# DA1469x register map
Vendor: Dialog; Series: DA1469x; File version: 1.2
CPU: CM33 r1p0, little endian, no MPU, FPU, 3 interrupt priority bits
Registers are 32-bit, read-write, reset 0x0 unless marked. A register's access mark holds for its fields unless they carry their own. Offsets are from the block's base; [hi:lo] are bit positions.

## CHARGER (part 2 of 2) — CHARGER registers
Base 0x50040400
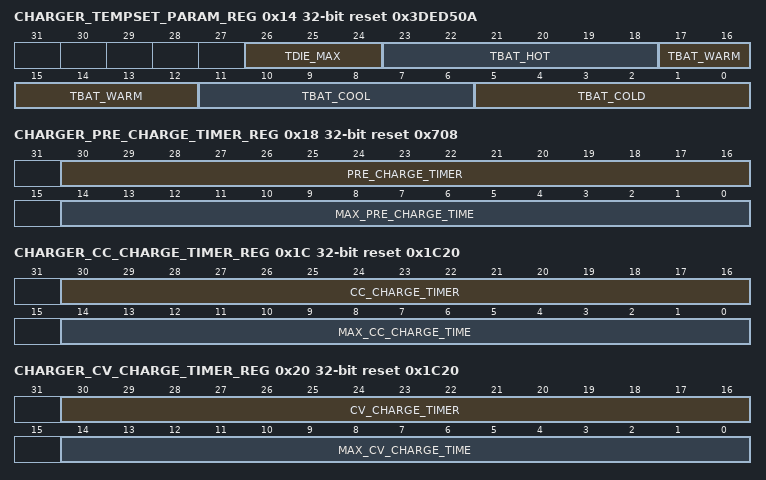
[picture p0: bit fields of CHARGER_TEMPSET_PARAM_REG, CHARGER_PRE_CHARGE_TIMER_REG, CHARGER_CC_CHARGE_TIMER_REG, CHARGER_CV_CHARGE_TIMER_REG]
0x14 CHARGER_TEMPSET_PARAM_REG reset 0x3DED50A — Charger battery temperature settings register
  [26:24] TDIE_MAX — This bit-field determines the maximum Die temperature level limit, ranging from 0C to 130C, according to the following encoding: 000: 0 C (mainly for test purposes) 001: 50 C 010: 80 C 011: 90 C 100: 100 C 101: 110 C 110: 120 C 111: 130 C
  [23:18] TBAT_HOT — This bit-field determines the battery temperature above which the charge current is zero, defining the "Hot" battery temperature zone. It ranges from minus 10C to 53C. The range is the same with the one defined in detail in TBAT_COLD bit-field.
  [17:12] TBAT_WARM — This bit-field determines the battery temperature above which the charge current is reduced, defining the "Warm" temperature zone. It ranges from minus 10C to 53C. The range is the same with the one defined in detail in TBAT_COLD bit-field.
  [11:6] TBAT_COOL — This bit-field determines the battery temperature below which the charge current is reduced, defining the "Cool" temperature zone. It ranges from minus 10C to 53C and the range is the same with the one defined in TBAT_COLD bit-field.
  [5:0] TBAT_COLD — This bit-field determines the battery temperature below which the charge current is zero, defining the "Cold" temperature zone. It ranges from minus 10C to 53C, according to the following encoding: 0 : -10 C 1 : -9 C 2 : -8 C 3 : -7 C 4 : -6 C 5 : -5 C 6 : -4 C 7 : -3 C 8 : -2 C 9 : -1 C 10 : 0 C 11 : 1 C 12 : 2 C 13 : 3 C 14 : 4 C 15 : 5 C 16 : 6 C 17 : 7 C 18 : 8 C 19 : 9 C 20 : 10 C 21 : 11 C 22 : 12 C 23 : 13 C 24 : 14 C 25 : 15 C 26 : 16 C 27 : 17 C 28 : 18 C 29 : 19 C 30 : 20 C 31 : 21 C 32 : 22 C 33 : 23 C 34 : 24 C 35 : 25 C 36 : 26 C 37 : 27 C 38 : 28 C 39 : 29 C 40 : 30 C 41 : 31 C 42 : 32 C 43 : 33 C 44 : 34 C 45 : 35 C 46 : 36 C 47 : 37 C 48 : 38 C 49 : 39 C 50 : 40 C 51 : 41 C 52 : 42 C 53 : 43 C 54 : 44 C 55 : 45 C 56 : 46 C 57 : 47 C 58 : 48 C 59 : 49 C 60 : 50 C 61 : 51 C 62 : 52 C 63 : 53 C
0x18 CHARGER_PRE_CHARGE_TIMER_REG reset 0x708 — Maximum pre-charge time limit register
  [30:16] PRE_CHARGE_TIMER ro — Returns the current value of the Pre-Charge timeout counter, running at a 1Hz clock. The range of the specific timer is identical to the one of the CC-Charge and the CV-Charge timers, so it may count up to 6 hours, ranging from 0 to MAX_PRE_CHARGE_TIME. It is reset to 0 when the Charger's FSM is either in DISABLED or in END_OF_CHARGE state.
  [14:0] MAX_PRE_CHARGE_TIME — This bit-field determines the maximum time (measured in ticks of the Charger's 1Hz clock) allowed for the Pre-Charge stage. If this is exceeded, a Pre-Charge time-out error will be captured by the Charger's control unit and its FSM will move to the respective state (ERROR). In order to exit this state and re-start charging, the CHARGER_RESUME bit-field of CHARGER_CTRL_REG must be set. Note: The specific bit-field should be always set to a non-zero value.
0x1C CHARGER_CC_CHARGE_TIMER_REG reset 0x1C20 — Maximum CC-charge time limit register
  [30:16] CC_CHARGE_TIMER ro — Returns the current value of the CC-Charge timeout counter, running at a 1Hz clock. The range of the specific timer is identical to the one of the Pre-Charge and the CV-Charge timers, so it may count up to 6 hours, ranging from 0 to MAX_CC_CHARGE_TIME. It is reset to 0 when the Charger's FSM is either in DISABLED or in END_OF_CHARGE state.
  [14:0] MAX_CC_CHARGE_TIME — This bit-field determines the maximum time (measured in ticks of the Charger's 1Hz clock) allowed for the CC (Constant Current) charging stage. If this is exceeded, a CC charge time-out error will be captured by the Charger's control unit and its FSM will move to the ERROR state. In order to exit this state and re-start charging, the CHARGER_RESUME bit-field of CHARGER_CTRL_REG must be set. Note: The specific bit-field should be always set to a non-zero value.
0x20 CHARGER_CV_CHARGE_TIMER_REG reset 0x1C20 — Maximum CV-charge time limit register
  [30:16] CV_CHARGE_TIMER ro — Returns the current value of the CV-Charge timeout counter, running at a 1Hz clock. The range of the specific timer is identical to the one of the Pre-Charge and the CC-Charge timers, so it may count up to 6 hours, ranging from 0 to MAX_CV_CHARGE_TIME. It is reset to 0 when the Charger's FSM is either in DISABLED or in END_OF_CHARGE state.
  [14:0] MAX_CV_CHARGE_TIME — This bit-field determines the maximum time (measured in ticks of the Charger's 1Hz clock) allowed for the CV (Constant Voltage) charging stage. If this is exceeded, a CV charge time-out error will be captured by the Charger's control unit and its FSM will move to the ERROR state. In order to exit this state and re-start charging, the CHARGER_RESUME bit-field of CHARGER_CTRL_REG must be set. Note: The specific bit-field should be always set to a non-zero value.
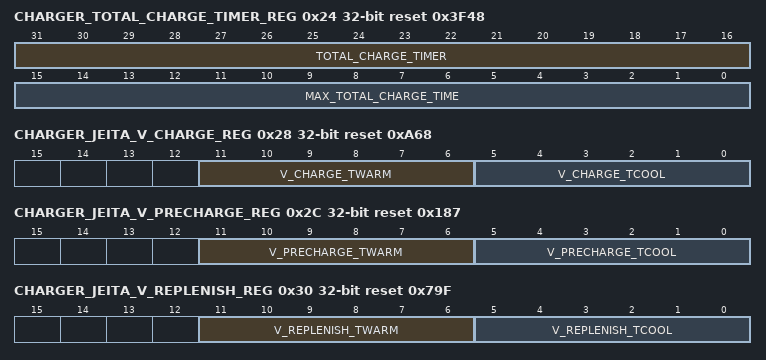
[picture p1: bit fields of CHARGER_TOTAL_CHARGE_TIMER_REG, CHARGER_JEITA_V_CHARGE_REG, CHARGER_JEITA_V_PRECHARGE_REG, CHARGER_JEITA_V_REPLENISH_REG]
0x24 CHARGER_TOTAL_CHARGE_TIMER_REG reset 0x3F48 (reset mask 0x7FFFFFFF) — Maximum total charge time limit register
  [31:16] TOTAL_CHARGE_TIMER ro — Returns the current value of the overall charge timeout counter, running at a 1Hz clock. This timer has been set to 16 bits, so that it can count up to 10.5 hours, and ranges from 0 to MAX_TOTAL_CHARGE_TIME. It is reset to 0 when the Charger's FSM is either in DISABLED or in END_OF_CHARGE state.
  [15:0] MAX_TOTAL_CHARGE_TIME — This bit-field determines the maximum overall charging time allowed (measured in ticks of the 1Hz clock). If this is exceeded, a total charge time-out error will be captured by the Charger's controller and its FSM will move to the ERROR state. An IRQ will be also generated if the respective IRQ mask bit of CHARGER_ERROR_IRQ_MASK_REG is already set. In order to to exit this state, the "CHARGER_RESUME" bit-field of CHARGER_CTRL_REG must be set, to enable the Charger's FSM switch from ERROR to DISABLED state and start-over. Note: The specific bit-field should be always set to a non-zero value.
0x28 CHARGER_JEITA_V_CHARGE_REG reset 0xA68 — JEITA-compliant Charge voltage settings register
  [11:6] V_CHARGE_TWARM — Charge voltage setting for the Warm battery temperature zone. Regarding the range of values of this bit-field, see also the description of V_CHARGE field of CHARGER_VOLTAGE_PARAM_REG register.
  [5:0] V_CHARGE_TCOOL — Charge voltage setting for the Cool battery temperature zone. Regarding the range of values of this bit-field, see also the description of V_CHARGE field of CHARGER_VOLTAGE_PARAM_REG register.
0x2C CHARGER_JEITA_V_PRECHARGE_REG reset 0x187 — JEITA-compliant Pre-Charge voltage settings register
  [11:6] V_PRECHARGE_TWARM — Pre-Charge voltage setting for the Warm battery temperature zone. Regarding the range of values of this bit-field, see also the description of V_CHARGE field of CHARGER_VOLTAGE_PARAM_REG register.
  [5:0] V_PRECHARGE_TCOOL — Pre-Charge current setting for the Cool battery temperature zone. Regarding the range of values of this bit-field, see also the description of V_CHARGE field of CHARGER_VOLTAGE_PARAM_REG register.
0x30 CHARGER_JEITA_V_REPLENISH_REG reset 0x79F — JEITA-compliant Replenish settings register
  [11:6] V_REPLENISH_TWARM — Replenish voltage setting for the Warm battery temperature zone. Regarding the range of values of this bit-field, see also the description of V_CHARGE field of CHARGER_VOLTAGE_PARAM_REG.
  [5:0] V_REPLENISH_TCOOL — Replenish voltage setting for the Cool battery temperature zone. Regarding the range of values of this bit-field, see also the description of V_CHARGE field of CHARGER_VOLTAGE_PARAM_REG.
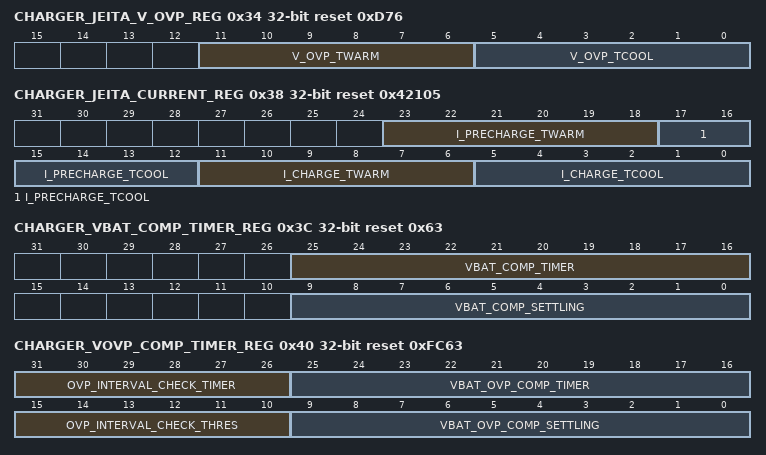
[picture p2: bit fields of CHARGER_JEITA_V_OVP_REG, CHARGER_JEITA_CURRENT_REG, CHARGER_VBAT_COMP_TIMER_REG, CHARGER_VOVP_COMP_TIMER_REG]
0x34 CHARGER_JEITA_V_OVP_REG reset 0xD76 — JEITA-compliant OVP settings register
  [11:6] V_OVP_TWARM — VBAT Over-voltage Protection (OVP) setting for the Warm battery temperature zone.Regarding the range of values of this bit-field, see also the description of V_CHARGE field of CHARGER_VOLTAGE_PARAM_REG.
  [5:0] V_OVP_TCOOL — VBAT Over-voltage Protection (OVP) setting for the Cool battery temperature zone.Regarding the range of values of this bit-field, see also the description of V_CHARGE field of CHARGER_VOLTAGE_PARAM_REG.
0x38 CHARGER_JEITA_CURRENT_REG reset 0x42105 — JEITA-compliant current settings register
  [23:18] I_PRECHARGE_TWARM — Pre-Charge current setting for the Warm battery temperature zone. Regarding the range of values of this bit-field, see also the description of I_PRECHARGE field of CHARGER_CURRENT_PARAM_REG register.
  [17:12] I_PRECHARGE_TCOOL — Pre-Charge current setting for the Cool battery temperature zone. Regarding the range of values of this bit-field, see also the description of I_PRECHARGE field of CHARGER_CURRENT_PARAM_REG register.
  [11:6] I_CHARGE_TWARM — Charge current setting for the Warm battery temperature pack zone. Regarding the range of values of this bit-field, see also the description of I_CHARGE field of CHARGER_CURRENT_PARAM_REG register.
  [5:0] I_CHARGE_TCOOL — Charge current setting for the "COOL" battery temperature level. Regarding the range of values of this bit-field, see also the description of I_CHARGE field of CHARGER_CURRENT_PARAM_REG register.
0x3C CHARGER_VBAT_COMP_TIMER_REG reset 0x63 — Main Vbat comparator timer register
  [25:16] VBAT_COMP_TIMER ro — Returns the current value of the timer used to determine when the output of the Vbat comparator (checking Vbat vs Pre_Charge and Replenish levels) must be sampled by the digital. As soon as the timer expires (down-counting to 0, starting from the value set in VBAT_COMP_SETTLING), the comparator's output is latched by the Charger's digital block and used by the FSM. Note: When the Charger's FSM is in BYPASSED state, this timer is kept to zero and the SW takes over. In this mode, the specific comparator checks the level of Vbat against the Pre-Charge level. Hence, SW can periodically sample the status of this comparator by reading the MAIN_VBAT_COMP_OUT bit-field of CHARGER_STATUS_REG, to determine if Vbat has exceeded the Pre-Charge level or not.
  [9:0] VBAT_COMP_SETTLING — Settling time threshold (in us) for the Vbat comparator checking Vbat vs the programmed Pre-Charge and Replenish levels. The settings (voltage levels) of the comparator are controlled by the digital block of the Charger and they are driven based on the state of the main FSM (PRE_CHARGE, END_OF_CHARGE).
0x40 CHARGER_VOVP_COMP_TIMER_REG reset 0xFC63 (reset mask 0x7FFFFFFF) — Vbat OVP comparator timer register
  [31:26] OVP_INTERVAL_CHECK_TIMER ro — The specific bit-field determines the current state of the timer used to periodically check the output of the Over-Voltage Protection comparator's output signal, as soon as the Charger's FSM reaches any of the charging states (PRE/CC/CV_CHARGE). When this happens, the timer starts ticking with the 1Mhz clock, ranging from 0 up to the programmed interval threshold (see also OVP_INTERVAL_CHECK_THRES field). As soon as this timer reaches the programmed threshold value, the Vbat OVP comparator's output is evaluated, increasing or not the counter keeping the consecutive OVP events. It is noted that out of the charging states, the specific timer is kept frozen to zero, not counting. Note : See also the OVP_OCCURRENCES_CNT bit-field of CHARGER_STATUS_REG for the consecutive OVP events counter.
  [25:16] VBAT_OVP_COMP_TIMER ro — Returns the current value of the timer used to determine when the Vbat Over-Voltage protection (OVP) comparator's output must be sampled by the digital. As soon as the timer expires (down-counting to 0, starting from VBAT_OVP_COMP_SETTLING), the comparator's output is latched by the Charger's digital block and used by the main FSM. Note: When the Charger's FSM is in BYPASSED state, this timer is kept to zero and the SW takes over, sampling the status of the VBAT_OVP_COMP_OUT bit-field of CHARGER_STATUS_REG to determine if the Vbat has exceeded the OVP limit.
  [15:10] OVP_INTERVAL_CHECK_THRES — This bit-field determines the periodic interval of checking the dedicated Vbat OVP comparator's output, when the Charger's FSM is in any of the charging states (PRE/CC/CV_CHARGE). The implementation is based on a dedicated timer, counting from zero up to the value programmed into this bit-field (see also OVP_INTERVAL_CHECK_TIMER field's description) and only when the FSM is in any of the three charging states. Out of these states, the timer is kept frozen to zero. As soon as this timer reaches the programmed threshold, the Vbat OVP comparator's output is sampled and depending on its level, (high or low), another counter, keeping the number of consecutive OVP events, is increased or not. The programmed threshold value should always be non-zero. Note: See also the OVP_DEBOUNCE_CNT bit-field of CHARGER_STATUS_REG, for the consecutive OVP events counter.
  [9:0] VBAT_OVP_COMP_SETTLING — Settling time threshold (in us) for the Vbat comparator checking Vbat vs the programmed Over-Voltage level.
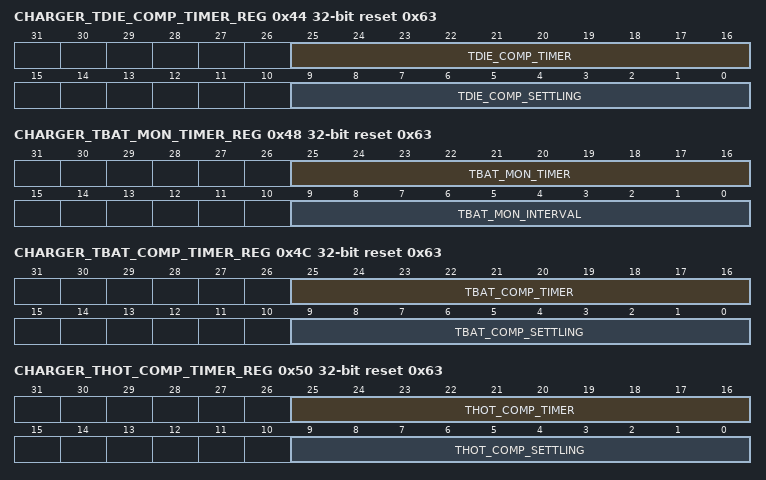
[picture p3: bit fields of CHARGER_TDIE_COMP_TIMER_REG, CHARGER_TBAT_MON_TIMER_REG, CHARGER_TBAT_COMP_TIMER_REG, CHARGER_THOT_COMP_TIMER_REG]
0x44 CHARGER_TDIE_COMP_TIMER_REG reset 0x63 — Die temperature comparator timer register
  [25:16] TDIE_COMP_TIMER ro — Returns the current value of the timer used to determine when the Die temperature comparator's output must be sampled by the digital. As soon as the timer expires (down-counting to 0, starting from TDIE_COMP_SETTLING) the comparator's output is latched by the Charger's digital block and used by the main FSM. After expiring, the timer starts-over again, down-counting, to enable the continuous monitoring of Die temperature by the digital. Note: When the Charger's FSM is in BYPASSED state, this timer is kept to zero and the SW takes over, sampling the status of the TDIE_PROT_COMP_OUT bit-field of CHARGER_STATUS_REG to determine if the Die temperature limit has been exceeded.
  [9:0] TDIE_COMP_SETTLING — Settling time threshold (in us) for the Die temperature comparator.
0x48 CHARGER_TBAT_MON_TIMER_REG reset 0x63 — Battery temperature monitor interval timer
  [25:16] TBAT_MON_TIMER ro — This is the battery temperature monitoring timer, counting with the Charger's 1KHz clock. If the battery monitor mode is accordingly set in the TBAT_MONITOR_MODE bit-field of CHARGER_CTRL_REG (so either to 0x1 or 0x2), this timer is initially loaded with the value set in TBAT_MON_INTERVAL bit-field in the subsequent 1khz cycles starts down-counting to 0. As soon as the specific timer expires,the JEITA FSM starts-over again, to refresh the battery temperature status.
  [9:0] TBAT_MON_INTERVAL — Timing interval (in ms) for the Battery temperature monitoring. This interval determines how often the JEITA FSM will be checking and potentially refreshing the Battery temperature status, by selecting accordingly the proper level (Hot, Cold, Warm, Cool or Normal), based on the feedback of the two battery temperature comparators being present in the Charger's analogue circuitry (one for the Hot level and one for Cold, Cool and Warm, to support JEITA). Note: The specific bit-field should be always set to a non-zero value.
0x4C CHARGER_TBAT_COMP_TIMER_REG reset 0x63 — Battery temperature (main) comparator timer
  [25:16] TBAT_COMP_TIMER ro — Returns the main battery temperature comparator's timer, used for the latching of the comparator's output. The output of the comparator is used by the JEITA FSM, to determine the current battery temperature pack's status.
  [9:0] TBAT_COMP_SETTLING — Settling time (specified in us) for the main battery temperature comparator, checking for the "COOL", "COLD" and "WARM" levels. The charger's digital block uses a dedicated timer to sample the specific comparator's output. The comparator's output is latched as soon as the timer expires, reaching 0. Then, the timer is reloaded with the settling time value and starts-over, down-counting to 0. Note: The specific bit-field should be always set to a non-zero value.
0x50 CHARGER_THOT_COMP_TIMER_REG reset 0x63 — Battery temperature comparator timer for "Hot" zone
  [25:16] THOT_COMP_TIMER ro — Returns the battery temperature comparator's timer dedicated for the "Hot" level.
  [9:0] THOT_COMP_SETTLING — Charger's battery temperature comparator settling time (specified in us), specifically for the Hot temperature zone. The charger's digital block uses a dedicated timer to sample the specific comparator's output. The comparator's output is latched as soon as the timer expires, reaching 0. Then, the timer is reloaded with the settling time value and starts-over again Note: The specific bit-field should be always set to a non-zero value.
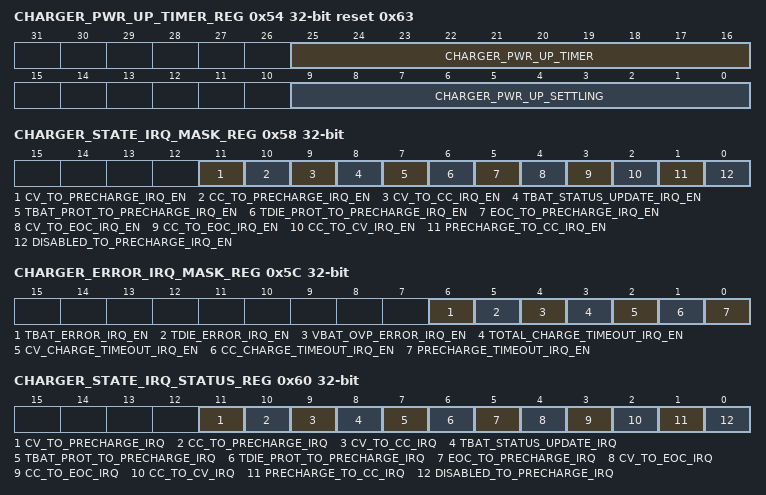
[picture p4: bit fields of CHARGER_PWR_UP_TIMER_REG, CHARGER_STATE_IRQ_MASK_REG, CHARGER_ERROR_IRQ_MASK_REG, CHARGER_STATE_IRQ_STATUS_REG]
0x54 CHARGER_PWR_UP_TIMER_REG reset 0x63 — Charger power-up (settling) timer
  [25:16] CHARGER_PWR_UP_TIMER ro — Returns the current value of the charger's power-up timer, running with the 1Khz clock. Note: The specific timer is reset to the value programmed to CHARGER_PWR_UP_SETTLING bit-field, when the Charger's analogue circuitry has been enabled, after being disabled initially. By setting CHARGER_CTRL_REG[CHARGER_ENABLE] to '0', the analogue part is disabled and in order to be properly enable, SW has to wait for 1ms (one 1Khz clock period) time. The latter is is needed to ensure that the power-up timer's control signals in the Charger's digital part will be cleared when the analogue part is again enabled, so that a proper new start-up of the Charger's FSM is possible.
  [9:0] CHARGER_PWR_UP_SETTLING — This bit-field determines the charger's power-up (settling) time, required for the analogue circuitry of the charger. As soon as the charger is powered-on by setting the CHARGER_ENABLE bit-field of CHARGER_CTRL_REG, the charger's FSM loads a dedicated timer with this value and waits for this timer to expire, before proceeding to the next states. Note: The specific bit-field should be always set to a non-zero value.
0x58 CHARGER_STATE_IRQ_MASK_REG — Mask register of Charger FSM IRQs
  [11] CV_TO_PRECHARGE_IRQ_EN — When set, this bit-field enables the IRQ generation as soon as the Charger's FSM switches from CV_CHARGE to PRE_CHARGE state.
  [10] CC_TO_PRECHARGE_IRQ_EN — When set, this bit-field enables the IRQ generation as soon as the Charger's FSM switches from CC_CHARGE to PRE_CHARGE state.
  [9] CV_TO_CC_IRQ_EN — When set, this bit-field enables the IRQ generation as soon as the Charger's FSM switches from CV_CHARGE to CC_CHARGE state.
  [8] TBAT_STATUS_UPDATE_IRQ_EN — When set, this bit-field enables the generation of the Charger's state IRQ as soon as the battery temperature status is refreched by the Charger's Battery temperature monitor (JEITA) FSM. As soon as the specific FSM checks the current battery temperature level, it notifies the main Charger FSM that it has run and that the Battery temperature pack state is checked (and potentially refreshed with a new status).
  [7] TBAT_PROT_TO_PRECHARGE_IRQ_EN — When set, this bit-field enables the Charger's state IRQ generation as soon as the Charger's FSM switches from the Battery temperature protection state (TBAT_PROT) to PRE_CHARGE, resuming charging.
  [6] TDIE_PROT_TO_PRECHARGE_IRQ_EN — When set, this bit-field enables the Charger's state IRQ generation as soon as the Charger's FSM switches from the Die temperature protection state (TDIE_PROT) to PRE_CHARGE, resuming charging.
  [5] EOC_TO_PRECHARGE_IRQ_EN — When set, this bit-field enables the Charger's State IRQ generation as soon as the Charger's FSM switches from END_OF_CHARGE again to PRE_CHARGE state. This happens when the Vbat voltage level is detected to be below the Replenish level set.
  [4] CV_TO_EOC_IRQ_EN — When set, this bit-field enables the IRQ generation as soon as the Charger's FSM switches from CV_CHARGE to END_OF_CHARGE state.
  [3] CC_TO_EOC_IRQ_EN — When set, this bit-field enables the IRQ generation as soon as the Charger's FSM switches from CC_CHARGE to END_OF_CHARGE state.
  [2] CC_TO_CV_IRQ_EN — When set, this bit-field enables the IRQ generation as soon as the Charger's FSM switches from CC_CHARGE to CV_CHARGE state.
  [1] PRECHARGE_TO_CC_IRQ_EN — When set, this bit-field enables the IRQ generation as soon as the Charger's FSM switches from PRE_CHARGE to CC_CHARGE state..
  [0] DISABLED_TO_PRECHARGE_IRQ_EN — When set, this bit-field enables the IRQ generation as soon as the Charger's FSM switches from DISABLED to PRE_CHARGE state.
0x5C CHARGER_ERROR_IRQ_MASK_REG — Mask register of Charger Error IRQs
  [6] TBAT_ERROR_IRQ_EN — When set, it enables the generation of Battery temperature IRQs.The IRQ is generated as soon as the JEITA FSM detects that the battery temperature is either in the "Hot" or in the "Cold" temperature region, by sampling the respective comparators' output.
  [5] TDIE_ERROR_IRQ_EN — When set, it enables the generation of Die temperature error IRQs. The IRQ is generated as soon as a Die temperature error is captured, so as soon as the Charger's FSM moves to the TDIE_PROT state. For this to happen, the Die temperature comparator should indicate that Die temperature has exceeded the limit defined in CHARGER_TEMPSET_PARAM_REG.TDIE_MAX.
  [4] VBAT_OVP_ERROR_IRQ_EN — When set, it enables the generation of VBAT_OVP IRQs. The IRQ is generated as soon as the dedicated Vbat comparator shows that Vbat has exceeded the OVP level and the Charger's FSM has switched to the respective error state ("ERROR").
  [3] TOTAL_CHARGE_TIMEOUT_IRQ_EN — When set, it enables the total charge timeout IRQs. The IRQ is generated as soon as the Charger's global charge timer expires, reaching 0.
  [2] CV_CHARGE_TIMEOUT_IRQ_EN — When set, it enables the CV charge timeout IRQs. The IRQ is generated as soon as the Charger's state timer expires, reaching 0 when the FSM is in the CV_CHARGE state.
  [1] CC_CHARGE_TIMEOUT_IRQ_EN — When set, it enables the CC charge timeout IRQs. The IRQ is generated as soon as the Charger's state timer, expires, reaching 0.
  [0] PRECHARGE_TIMEOUT_IRQ_EN — When set, it enables the Pre-Charge timeout IRQs. The IRQ is generated as soon as the Charger's state timer expires, reaching 0.
0x60 CHARGER_STATE_IRQ_STATUS_REG — Status register of Charger FSM IRQs
  [11] CV_TO_PRECHARGE_IRQ ro — 0 = No transition of the Charger's FSM from CV_CHARGE to PRE_CHARGE state has been captured 1 = Charger's FSM has switched from CV_CHARGE to PRE_CHARGE state
  [10] CC_TO_PRECHARGE_IRQ ro — 0 = No transition of the Charger's FSM from CC_CHARGE to PRE_CHARGE state has been captured 1 = Charger's FSM has switched from CC_CHARGE to PRE_CHARGE state
  [9] CV_TO_CC_IRQ ro — 0 = No transition of the Charger's FSM from CV_CHARGE to CC_CHARGE state has been captured 1 = Charger's FSM has switched from CV_CHARGE to CC_CHARGE state
  [8] TBAT_STATUS_UPDATE_IRQ ro — 0 = No battery temperature status update event has been captured 1 = Battery temperature pack's status has been checked and refreshed by the Charger's Battery temperature monitor FSM. Thus, the new status of the battery temperature should be checked by SW.
  [7] TBAT_PROT_TO_PRECHARGE_IRQ ro — 0 = No transition of the Charger's FSM from TBAT_PROT to PRE_CHARGE state has been captured 1 = Charger's FSM has switched from TBAT_PROT to PRE_CHARGE state, resuming charging after having recovered from a battery temperature error.
  [6] TDIE_PROT_TO_PRECHARGE_IRQ ro — 0 = No transition of the Charger's FSM from TDIE_PROT to PRE_CHARGE state has been captured 1 = Charger's FSM has switched from TDIE_PROT to PRE_CHARGE state, resuming charging after having recovered from a Die temperature error.
  [5] EOC_TO_PRECHARGE_IRQ ro — 0 = No transition of the Charger's FSM from END_OF_CHARGE to PRE_CHARGE state has been captured 1 = Charger's FSM has switched from END_OF_CHARGE to PRE_CHARGE state
  [4] CV_TO_EOC_IRQ ro — 0 = No transition of the Charger's FSM from CV_CHARGE to END_OF_CHARGE state has been captured 1 = Charger's FSM has switched from CV_CHARGE to END_OF_CHARGE state
  [3] CC_TO_EOC_IRQ ro — 0 = No transition of the Charger's FSM from CC_CHARGE to END_OF_CHARGE state has been captured 1 = Charger's FSM has switched from CC_CHARGE to END_OF_CHARGE state
  [2] CC_TO_CV_IRQ ro — 0 = No transition of the Charger's FSM from CC_CHARGE to CV_CHARGE state has been captured 1 = Charger's FSM has switched from CC_CHARGE to CV_CHARGE state
  [1] PRECHARGE_TO_CC_IRQ ro — 0 = No transition of the Charger's FSM from PRE_CHARGE to CC_CHARGE state has been captured 1 = Charger's FSM has switched from PRE_CHARGE to CC_CHARGE state
  [0] DISABLED_TO_PRECHARGE_IRQ ro — 0 = No transition of the Charger's FSM from DISABLED to PRE_CHARGE state has been captured 1 = Charger's FSM has switched from DISABLED to PRE_CHARGE state
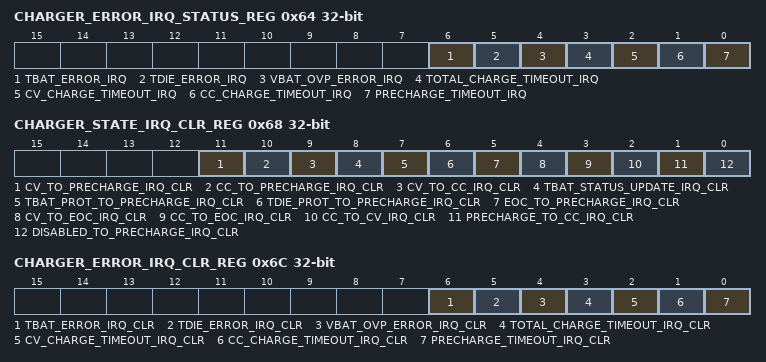
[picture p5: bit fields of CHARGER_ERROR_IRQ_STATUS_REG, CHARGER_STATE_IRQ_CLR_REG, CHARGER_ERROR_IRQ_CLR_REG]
0x64 CHARGER_ERROR_IRQ_STATUS_REG — Status register of Charger Error IRQs
  [6] TBAT_ERROR_IRQ ro — 0 = No Battery temperature error IRQ event is captured, so charging may continue 1 = A Battery temperature error IRQ event has been captured, declaring that the Charger's FSM has moved to the respective error state (TBAT_PROT). Note : The status bit is updated automatically when the Battery temperature is detected to be either in the HOT or in the COLD zone, regardless of the state of the respective IRQ mask bit.
  [5] TDIE_ERROR_IRQ ro — 0 = No Die temperature error IRQ events have been captured, so charging may continue 1 = A Die temperature error IRQ event is captured, declaring that the Charger's FSM has switched to the respective error state (TDIE_PROT) and charging will be automatically stopped. Note : The status bit is updated automatically when a Die temperature error is detected, thus when the die temperature is found to have exceeded the programmed level, regardless of the stae of the respective IRQ mask bit.
  [4] VBAT_OVP_ERROR_IRQ ro — 0 = Vbat has not exceeded the Over-Voltage Protection (OVP) level, so charging may continue 1 = Vbat has exceeded the Over-Voltage level, thus an OVP error event has been captured. The Charger's FSM switches to the respective error state (ERROR) as soon as the OVP event is captured by the digital part of the Charger and charging will be automatically stopped.
  [3] TOTAL_CHARGE_TIMEOUT_IRQ ro — 0 = Total charge time counter has not yet reached the maximum charge time (set in CHARGER_TOTAL_CHARGE_TIME_REG) 1 = Total charge time counter has reached the maximum charge time programmed. The Charger's FSM will move to the respective error state (ERROR) and charging will be automatically stopped, as soon as the specific event is captured.
  [2] CV_CHARGE_TIMEOUT_IRQ ro — 0 = State charge time counter has not yet reached the maximum CV charge time (set in CHARGER_CV_CHARGE_TIME_REG) 1 = Total charge time counter has reached the maximum CV charge time programmed. The Charger's FSM will move to the respective error state (ERROR) and charging will be automatically stopped, as soon as the specific event is captured.
  [1] CC_CHARGE_TIMEOUT_IRQ ro — 0 = State charge time counter has not yet reached the maximum CC charge time (set in CHARGER_CC_CHARGE_TIME_REG) 1 = Total charge time counter has reached the maximum CC charge time programmed. The Charger's FSM will move to the respective error state (ERROR) and charging will be automatically stopped, as soon as the specific event is captured.
  [0] PRECHARGE_TIMEOUT_IRQ ro — 0 = State charge time counter has not yet reached the maximum Pre-charge time (set in CHARGER_PRECHARGE_TIME_REG) 1 = Total charge time counter has reached the maximum Pre-charge time programmed. The Charger's FSM will move to the respective error state (ERROR) and charging will be automatically stopped, as soon as the specific event is captured.
0x68 CHARGER_STATE_IRQ_CLR_REG — Interrupt clear register of Charger FSM IRQs
  [11] CV_TO_PRECHARGE_IRQ_CLR wo — Writing a 1 will reset the respective Charger's State IRQ status bit ; writing a 0 will have no effect
  [10] CC_TO_PRECHARGE_IRQ_CLR wo — Writing a 1 will reset the respective Charger's State IRQ status bit ; writing a 0 will have no effect
  [9] CV_TO_CC_IRQ_CLR wo — Writing a 1 will reset the respective Charger's State IRQ status bit ; writing a 0 will have no effect
  [8] TBAT_STATUS_UPDATE_IRQ_CLR wo — Writing a 1 will reset the Battery temperature status update IRQ status bit ; writing a 0 will have no effect
  [7] TBAT_PROT_TO_PRECHARGE_IRQ_CLR wo — Writing a 1 will reset the respective Charger's State IRQ status bit ; writing a 0 will have no effect
  [6] TDIE_PROT_TO_PRECHARGE_IRQ_CLR wo — Writing a 1 will reset the respective Charger's State IRQ status bit ; writing a 0 will have no effect
  [5] EOC_TO_PRECHARGE_IRQ_CLR wo — Writing a 1 will reset the respective Charger's State IRQ status bit ; writing a 0 will have no effect
  [4] CV_TO_EOC_IRQ_CLR wo — Writing a 1 will reset the respective Charger's State IRQ status bit ; writing a 0 will have no effect
  [3] CC_TO_EOC_IRQ_CLR wo — Writing a 1 will reset the respective Charger's State IRQ status bit ; writing a 0 will have no effect
  [2] CC_TO_CV_IRQ_CLR wo — Writing a 1 will reset the respective Charger's State IRQ status bit ; writing a 0 will have no effect
  [1] PRECHARGE_TO_CC_IRQ_CLR wo — Writing a 1 will reset the respective Charger's State IRQ status bit ; writing a 0 will have no effect
  [0] DISABLED_TO_PRECHARGE_IRQ_CLR wo — Writing a 1 will reset the respective Charger's State IRQ status bit ; writing a 0 will have no effect
0x6C CHARGER_ERROR_IRQ_CLR_REG — Interrupt clear register of Charger Error IRQs
  [6] TBAT_ERROR_IRQ_CLR wo — Writing a 1 will reset the respective Charger's Error IRQ status bit ; writing a 0 will have no effect
  [5] TDIE_ERROR_IRQ_CLR wo — Writing a 1 will reset the respective Charger's Error IRQ status bit ; writing a 0 will have no effect
  [4] VBAT_OVP_ERROR_IRQ_CLR wo — Writing a 1 will reset the respective Charger's Error IRQ status bit ; writing a 0 will have no effect
  [3] TOTAL_CHARGE_TIMEOUT_IRQ_CLR wo — Writing a 1 will reset the respective Charger's Error IRQ status bit ; writing a 0 will have no effect
  [2] CV_CHARGE_TIMEOUT_IRQ_CLR wo — Writing a 1 will reset the respective Charger's Error IRQ status bit ; writing a 0 will have no effect
  [1] CC_CHARGE_TIMEOUT_IRQ_CLR wo — Writing a 1 will reset the respective Charger's Error IRQ status bit ; writing a 0 will have no effect
  [0] PRECHARGE_TIMEOUT_IRQ_CLR wo — Writing a 1 will reset the respective Charger's Error IRQ status bit ; writing a 0 will have no effect
